# f28p55x_dcsm_common_regs register map
Vendor: Texas Instruments
Peripheral module from a debugger description file (folder C2000).
Address unit: 16 bits
Registers are 32-bit, read-write, no defined reset value unless marked. A register's access mark holds for its fields unless they carry their own. Offsets are as the file gives them; lines under a group give offsets from that group; [hi:lo] are bit positions; {n}, {i} and the like mark numbered series; 'fields as' and 'values as' point back to an identical list; <NAME> marks a mode.

## DCSM_COMMON_REGS — DCSM COMMON Registers
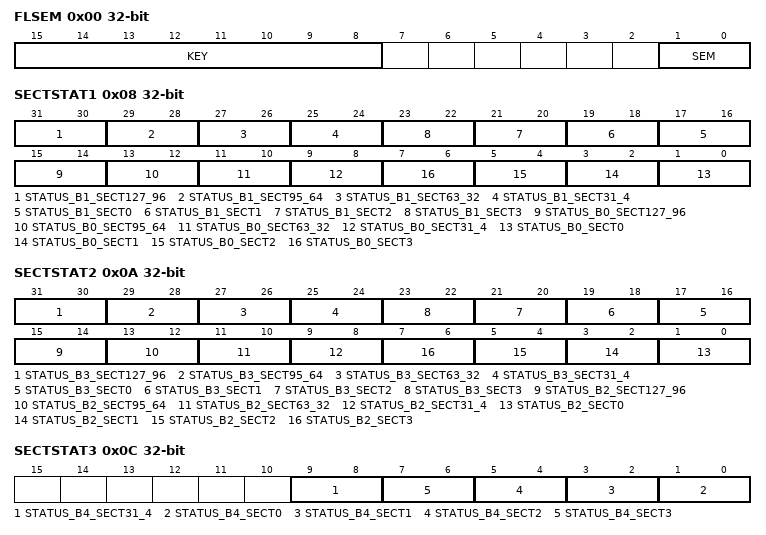
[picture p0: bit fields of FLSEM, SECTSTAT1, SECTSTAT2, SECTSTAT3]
0x00 FLSEM — Flash Wrapper Semaphore Register
  [15:8] KEY — Semaphore Key
  [1:0] SEM — Flash Semaphore Bit
0x08 SECTSTAT1 ro — Flash Sectors Status Register 1
  [31:30] STATUS_B1_SECT127_96 — Zone Status Flash Bank1 Sector 127-96
  [29:28] STATUS_B1_SECT95_64 — Zone Status Flash Bank1 Sector 95-64
  [27:26] STATUS_B1_SECT63_32 — Zone Status Flash Bank1 Sector 63-32
  [25:24] STATUS_B1_SECT31_4 — Zone Status Flash Bank1 Sector 31-4
  [2n+17:2n+16] STATUS_B1_SECT{n} (n=0..3) — Zone Status Flash Bank1 Sector {n}
  [15:14] STATUS_B0_SECT127_96 — Zone Status Flash Bank0 Sector 127-96
  [13:12] STATUS_B0_SECT95_64 — Zone Status Flash Bank0 Sector 95-64
  [11:10] STATUS_B0_SECT63_32 — Zone Status Flash Bank0 Sector 63-32
  [9:8] STATUS_B0_SECT31_4 — Zone Status Flash Bank0 Sector 31-4
  [2n+1:2n] STATUS_B0_SECT{n} (n=0..3) — Zone Status Flash Bank0 Sector {n}
0x0A SECTSTAT2 ro — Flash Sectors Status Register 2
  [31:30] STATUS_B3_SECT127_96 — Zone Status Flash Bank3 Sector 127-96
  [29:28] STATUS_B3_SECT95_64 — Zone Status Flash Bank3 Sector 95-64
  [27:26] STATUS_B3_SECT63_32 — Zone Status Flash Bank3 Sector 63-32
  [25:24] STATUS_B3_SECT31_4 — Zone Status Flash Bank3 Sector 31-4
  [2n+17:2n+16] STATUS_B3_SECT{n} (n=0..3) — Zone Status Flash Bank3 Sector {n}
  [15:14] STATUS_B2_SECT127_96 — Zone Status Flash Bank2 Sector 127-96
  [13:12] STATUS_B2_SECT95_64 — Zone Status Flash Bank2 Sector 95-64
  [11:10] STATUS_B2_SECT63_32 — Zone Status Flash Bank2 Sector 63-32
  [9:8] STATUS_B2_SECT31_4 — Zone Status Flash Bank2 Sector 31-4
  [2n+1:2n] STATUS_B2_SECT{n} (n=0..3) — Zone Status Flash Bank2 Sector {n}
0x0C SECTSTAT3 ro — Flash Sectors Status Register 3
  [9:8] STATUS_B4_SECT31_4 — Zone Status Flash Bank4 Sector 31-4
  [2n+1:2n] STATUS_B4_SECT{n} (n=0..3) — Zone Status Flash Bank4 Sector {n}
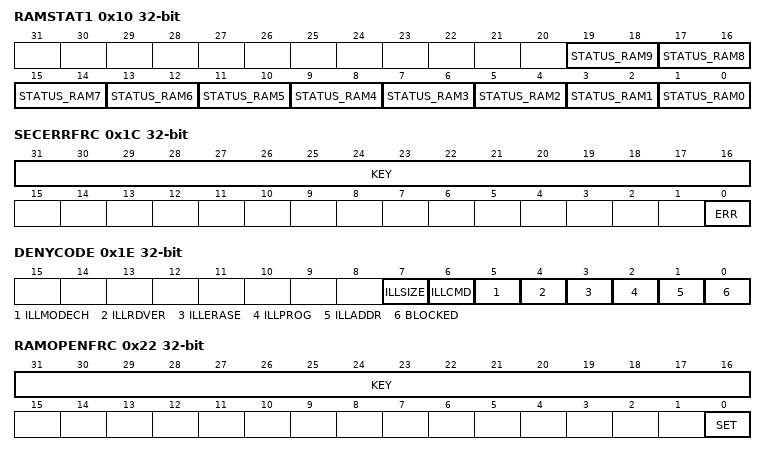
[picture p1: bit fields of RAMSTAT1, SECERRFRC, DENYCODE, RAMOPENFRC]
0x10 RAMSTAT1 ro — RAM Status Register 1
  [2n+1:2n] STATUS_RAM{n} (n=0..9) — Zone Status RAM LS{n}
0x18 SECERRSTAT ro — Security Error Status Register
  [0] ERR — Security Configuration load Error Status
0x1A SECERRCLR — Security Error Clear Register
  [0] ERR — Clear Security Configuration Load Error Status Bit
0x1C SECERRFRC — Security Error Force Register
  [31:16] KEY — Valid Register Write Key
  [0] ERR — Set Security Configuration Load Error Status Bit
0x1E DENYCODE ro — Flash Authorization Denial Code
  [7] ILLSIZE — Illegal Command Size
  [6] ILLCMD — Illegal Command
  [5] ILLMODECH — Illegal Mode Change
  [4] ILLRDVER — Illegal Read Verify Address
  [3] ILLERASE — Illegal Erase Address
  [2] ILLPROG — Illegal Program Address
  [1] ILLADDR — Illegal Address Code
  [0] BLOCKED — Blocked Code
0x20 RAMOPENSTAT ro — RAM Security Open Status Register
  [0] RAMOPEN — RAM Security Open
0x22 RAMOPENFRC — RAM Security Open Force Register
  [31:16] KEY — Valid Write KEY
  [0] SET — Set RAM Open request
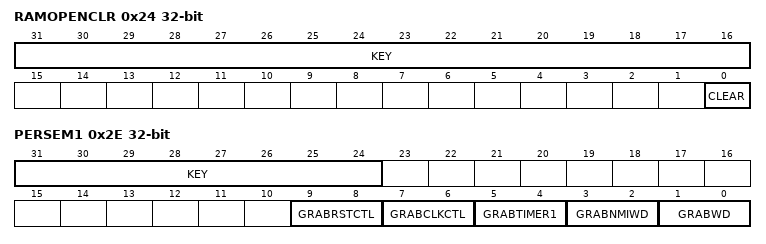
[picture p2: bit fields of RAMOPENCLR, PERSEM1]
0x24 RAMOPENCLR — RAM Security Open Clear Register
  [31:16] KEY — Valid Write KEY
  [0] CLEAR — Clear RAM Open request
0x26 RAMOPENLOCK
  [0] LOCK — RAMOPEN Lock
0x28 UID_UNIQUE_31_0 — Unique Identification Number Low
  [31:0] UID_L
0x2A UID_UNIQUE_63_32 — Unique Identification Number High
  [31:0] UID_H
0x2C PARTIDH — Part Identification High Register
  [31:0] ID — High Part Identification Number
0x2E PERSEM1 — Peripheral Semaphore Register
  [31:24] KEY — Semaphore Key
  [9:8] GRABRSTCTL — Grab Reset Configuration
  [7:6] GRABCLKCTL — Grab Clock Configuration
  [5:4] GRABTIMER1 — Grab TIMER1 module
  [3:2] GRABNMIWD — GRAB NMIWD module
  [1:0] GRABWD — Grab Watchdog module
